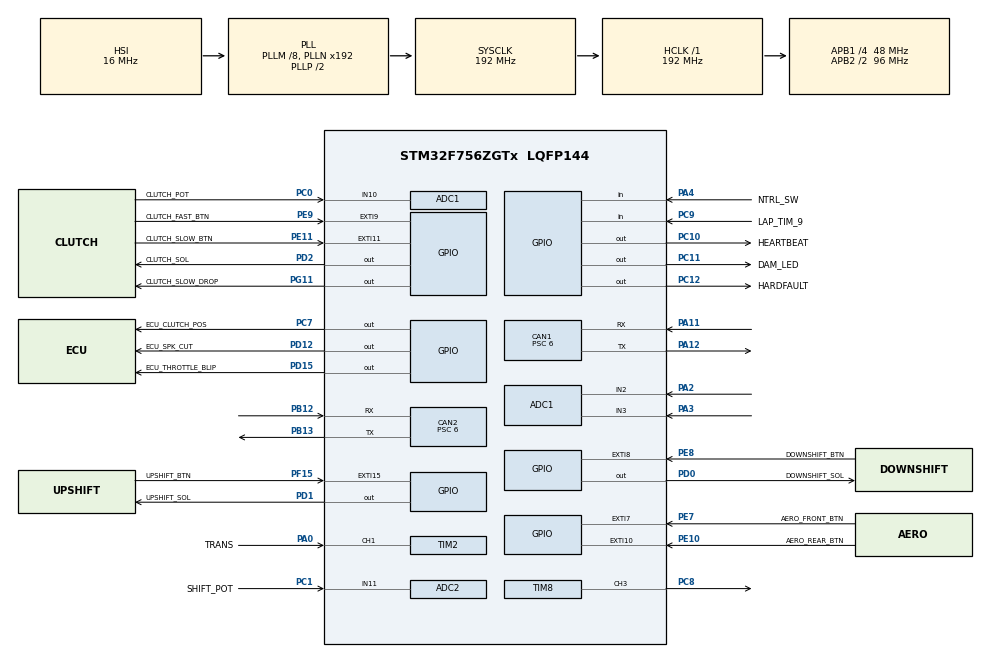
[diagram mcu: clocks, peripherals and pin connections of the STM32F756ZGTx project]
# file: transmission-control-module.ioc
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ADC1.Channel-1\#ChannelRegularConversion=ADC_CHANNEL_2
ADC1.Channel-2\#ChannelRegularConversion=ADC_CHANNEL_3
ADC1.Channel-3\#ChannelRegularConversion=ADC_CHANNEL_10
ADC1.ContinuousConvMode=ENABLE
ADC1.DMAContinuousRequests=ENABLE
ADC1.NbrOfConversion=3
ADC1.NbrOfConversionFlag=1
ADC1.Rank-1\#ChannelRegularConversion=1
ADC1.Rank-2\#ChannelRegularConversion=2
ADC1.Rank-3\#ChannelRegularConversion=3
ADC1.SamplingTime-1\#ChannelRegularConversion=ADC_SAMPLETIME_15CYCLES
ADC1.SamplingTime-2\#ChannelRegularConversion=ADC_SAMPLETIME_15CYCLES
ADC1.SamplingTime-3\#ChannelRegularConversion=ADC_SAMPLETIME_15CYCLES
ADC1.ScanConvMode=ADC_SCAN_ENABLE
ADC1.master=1
ADC2.Channel-0\#ChannelRegularConversion=ADC_CHANNEL_11
ADC2.ContinuousConvMode=ENABLE
ADC2.DMAContinuousRequests=ENABLE
ADC2.NbrOfConversionFlag=1
ADC2.Rank-0\#ChannelRegularConversion=1
ADC2.SamplingTime-0\#ChannelRegularConversion=ADC_SAMPLETIME_15CYCLES
CAN1.ABOM=ENABLE
CAN1.AWUM=ENABLE
CAN1.BS1=CAN_BS1_6TQ
CAN1.BS2=CAN_BS2_1TQ
CAN1.CalculateBaudRate=1000000
CAN1.CalculateTimeBit=1000
CAN1.CalculateTimeQuantum=125.0
CAN1.Mode=CAN_MODE_NORMAL
CAN1.Prescaler=6
CAN2.BS1=CAN_BS1_6TQ
CAN2.CalculateBaudRate=1000000
CAN2.CalculateTimeBit=1000
CAN2.CalculateTimeQuantum=125.0
CAN2.Prescaler=6
Dma.ADC1.1.Direction=DMA_PERIPH_TO_MEMORY
Dma.ADC1.1.FIFOMode=DMA_FIFOMODE_DISABLE
Dma.ADC1.1.Instance=DMA2_Stream0
Dma.ADC1.1.MemDataAlignment=DMA_MDATAALIGN_HALFWORD
Dma.ADC1.1.MemInc=DMA_MINC_ENABLE
Dma.ADC1.1.Mode=DMA_CIRCULAR
Dma.ADC1.1.PeriphDataAlignment=DMA_PDATAALIGN_HALFWORD
Dma.ADC1.1.PeriphInc=DMA_PINC_DISABLE
Dma.ADC1.1.Priority=DMA_PRIORITY_LOW
Dma.ADC2.0.Direction=DMA_PERIPH_TO_MEMORY
Dma.ADC2.0.FIFOMode=DMA_FIFOMODE_DISABLE
Dma.ADC2.0.Instance=DMA2_Stream2
Dma.ADC2.0.MemDataAlignment=DMA_MDATAALIGN_HALFWORD
Dma.ADC2.0.MemInc=DMA_MINC_ENABLE
Dma.ADC2.0.Mode=DMA_CIRCULAR
Dma.ADC2.0.PeriphDataAlignment=DMA_PDATAALIGN_HALFWORD
Dma.ADC2.0.PeriphInc=DMA_PINC_DISABLE
Dma.ADC2.0.Priority=DMA_PRIORITY_LOW
Dma.Request0=ADC2
Dma.Request1=ADC1
FREERTOS.Tasks01=taskMain_Loop,1,256,task_main_loop,Default,NULL,Dynamic,NULL,NULL;taskGCAN_TX,0,256,task_gcan_tx,Default,NULL,Dynamic,NULL,NULL;taskGCAN_RX,0,256,task_gcan_rx,Default,NULL,Dynamic,NULL,NULL
FREERTOS.configENABLE_FPU=1
FREERTOS.configMINIMAL_STACK_SIZE=256
FREERTOS.configUSE_NEWLIB_REENTRANT=1
Mcu.Family=STM32F7
Mcu.Name=STM32F756ZGTx
Mcu.Package=LQFP144
NVIC.CAN1_RX0_IRQn=true\:5\:0\:false\:false\:true\:true\:true\:true\:true
NVIC.CAN1_RX1_IRQn=true\:5\:0\:false\:false\:true\:true\:true\:true\:true
NVIC.CAN1_TX_IRQn=true\:5\:0\:false\:false\:true\:true\:true\:true\:true
NVIC.CAN2_RX0_IRQn=true\:5\:0\:false\:false\:true\:true\:true\:true\:true
NVIC.CAN2_RX1_IRQn=true\:5\:0\:false\:false\:true\:true\:true\:true\:true
NVIC.CAN2_TX_IRQn=true\:5\:0\:false\:false\:true\:true\:true\:true\:true
NVIC.DMA2_Stream0_IRQn=true\:5\:0\:false\:false\:true\:true\:false\:true\:true
NVIC.DMA2_Stream2_IRQn=true\:5\:0\:false\:false\:true\:true\:false\:true\:true
NVIC.EXTI15_10_IRQn=true\:5\:0\:false\:false\:true\:true\:true\:true\:true
NVIC.EXTI9_5_IRQn=true\:5\:0\:false\:false\:true\:true\:true\:true\:true
NVIC.PriorityGroup=NVIC_PRIORITYGROUP_4
NVIC.TIM1_UP_TIM10_IRQn=true\:5\:0\:false\:false\:true\:true\:true\:true\:true
NVIC.TIM2_IRQn=true\:5\:0\:false\:false\:true\:true\:true\:true\:true
NVIC.TIM6_DAC_IRQn=true\:0\:0\:false\:false\:true\:false\:false\:true\:true
NVIC.TimeBase=TIM6_DAC_IRQn
NVIC.TimeBaseIP=TIM6
PA0/WKUP.GPIO_Label=TRANS
PA0/WKUP.Signal=S_TIM2_CH1_ETR
PA11.Mode=CAN_Activate
PA11.Signal=CAN1_RX
PA12.Mode=CAN_Activate
PA12.Signal=CAN1_TX
PA2.Signal=ADCx_IN2
PA3.Signal=ADCx_IN3
PA4.GPIO_Label=NTRL_SW
PA4.Signal=GPIO_Input
PB12.Mode=CAN_Activate
PB12.Signal=CAN2_RX
PB13.Mode=CAN_Activate
PB13.Signal=CAN2_TX
PC0.GPIO_Label=CLUTCH_POT
PC0.Signal=ADCx_IN10
PC1.GPIO_Label=SHIFT_POT
PC1.Signal=ADCx_IN11
PC10.GPIO_Label=HEARTBEAT
PC10.Signal=GPIO_Output
PC11.GPIO_Label=DAM_LED
PC11.Signal=GPIO_Output
PC12.GPIO_Label=HARDFAULT
PC12.Signal=GPIO_Output
PC7.GPIO_Label=ECU_CLUTCH_POS
PC7.Signal=GPIO_Output
PC8.Signal=S_TIM8_CH3
PC9.GPIO_Label=LAP_TIM_9
PC9.GPIO_PuPd=GPIO_PULLDOWN
PC9.Signal=GPIO_Input
PD0.GPIO_Label=DOWNSHIFT_SOL
PD0.Signal=GPIO_Output
PD1.GPIO_Label=UPSHIFT_SOL
PD1.Signal=GPIO_Output
PD12.GPIO_Label=ECU_SPK_CUT
PD12.Signal=GPIO_Output
PD15.GPIO_Label=ECU_THROTTLE_BLIP
PD15.Signal=GPIO_Output
PD2.GPIO_Label=CLUTCH_SOL
PD2.Signal=GPIO_Output
PE10.GPIO_Label=AERO_REAR_BTN
PE10.GPIO_ModeDefaultEXTI=GPIO_MODE_IT_RISING_FALLING
PE10.Signal=GPXTI10
PE11.GPIO_Label=CLUTCH_SLOW_BTN
PE11.GPIO_ModeDefaultEXTI=GPIO_MODE_IT_RISING_FALLING
PE11.Signal=GPXTI11
PE7.GPIO_Label=AERO_FRONT_BTN
PE7.GPIO_ModeDefaultEXTI=GPIO_MODE_IT_RISING_FALLING
PE7.Signal=GPXTI7
PE8.GPIO_Label=DOWNSHIFT_BTN
PE8.GPIO_ModeDefaultEXTI=GPIO_MODE_IT_RISING_FALLING
PE8.Signal=GPXTI8
PE9.GPIO_Label=CLUTCH_FAST_BTN
PE9.GPIO_ModeDefaultEXTI=GPIO_MODE_IT_RISING_FALLING
PE9.Signal=GPXTI9
PF15.GPIO_Label=UPSHIFT_BTN
PF15.GPIO_ModeDefaultEXTI=GPIO_MODE_IT_RISING_FALLING
PF15.Signal=GPXTI15
PG11.GPIO_Label=CLUTCH_SLOW_DROP
PG11.Signal=GPIO_Output
ProjectManager.HeapSize=0x200
ProjectManager.StackSize=0x400
ProjectManager.TargetToolchain=STM32CubeIDE
RCC.AHBFreq_Value=192000000
RCC.APB1CLKDivider=RCC_HCLK_DIV4
RCC.APB1Freq_Value=48000000
RCC.APB1TimFreq_Value=96000000
RCC.APB2CLKDivider=RCC_HCLK_DIV2
RCC.APB2Freq_Value=96000000
RCC.APB2TimFreq_Value=192000000
RCC.CortexFreq_Value=192000000
RCC.HCLKFreq_Value=192000000
RCC.HSE_VALUE=25000000
RCC.HSI_VALUE=16000000
RCC.LSE_VALUE=32768
RCC.PLLM=8
RCC.PLLSAIN=50
RCC.SYSCLKFreq_VALUE=192000000
RCC.SYSCLKSource=RCC_SYSCLKSOURCE_PLLCLK
RCC.USBFreq_Value=192000000
RCC.VCOOutputFreq_Value=384000000
SH.ADCx_IN10.0=ADC1_IN10,IN10
SH.ADCx_IN11.0=ADC2_IN11,IN11
SH.ADCx_IN2.0=ADC1_IN2,IN2
SH.ADCx_IN3.0=ADC1_IN3,IN3
SH.S_TIM2_CH1_ETR.0=TIM2_CH1,Input_Capture1_from_TI1
SH.S_TIM8_CH3.0=TIM8_CH3,PWM Generation3 CH3
TIM2.Channel-Input_Capture1_from_TI1=TIM_CHANNEL_1
TIM2.Prescaler=6-1
TIM8.Channel-PWM\ Generation3\ CH3=TIM_CHANNEL_3
TIM8.Period=20000
TIM8.Prescaler=96
VP_FREERTOS_VS_CMSIS_V1.Mode=CMSIS_V1
VP_SYS_VS_tim6.Mode=TIM6
VP_TIM10_VS_ClockSourceINT.Mode=Enable_Timer
VP_TIM2_VS_ClockSourceINT.Mode=Internal
VP_TIM8_VS_ClockSourceINT.Mode=Internal
board=custom

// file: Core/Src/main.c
/* USER CODE BEGIN Header */
/**
  ******************************************************************************
  * @file           : main.c
  * @brief          : Main program body
  ******************************************************************************
  * @attention
  *
  * <h2><center>&copy; Copyright (c) 2021 STMicroelectronics.
  * All rights reserved.</center></h2>
  *
  * This software component is licensed by ST under BSD 3-Clause license,
  * the "License"; You may not use this file except in compliance with the
  * License. You may obtain a copy of the License at:
  *                        opensource.org/licenses/BSD-3-Clause
  *
  ******************************************************************************
  */
/* USER CODE END Header */
#include "main.h"
#include "cmsis_os.h"

/* USER CODE BEGIN Includes */
#include "DAM.h"
#include "main_task.h"

/* USER CODE END Includes */

 ADC_HandleTypeDef hadc1;
ADC_HandleTypeDef hadc2;
DMA_HandleTypeDef hdma_adc1;
DMA_HandleTypeDef hdma_adc2;

CAN_HandleTypeDef hcan1;
CAN_HandleTypeDef hcan2;

TIM_HandleTypeDef htim2;
TIM_HandleTypeDef htim8;
TIM_HandleTypeDef htim10;

osThreadId taskMain_LoopHandle;
osThreadId taskGCAN_TXHandle;
osThreadId taskGCAN_RXHandle;

void SystemClock_Config(void);
static void MX_GPIO_Init(void);
static void MX_DMA_Init(void);
static void MX_CAN1_Init(void);
static void MX_ADC1_Init(void);
static void MX_ADC2_Init(void);
static void MX_TIM10_Init(void);
static void MX_TIM2_Init(void);
static void MX_CAN2_Init(void);
static void MX_TIM8_Init(void);
void task_main_loop(void const * argument);
void task_gcan_tx(void const * argument);
void task_gcan_rx(void const * argument);

int main(void)
{

  /* MCU Configuration--------------------------------------------------------*/

  /* Reset of all peripherals, Initializes the Flash interface and the Systick. */
  HAL_Init();

  /* Configure the system clock */
  SystemClock_Config();

  /* USER CODE BEGIN SysInit */
  MX_DMA_Init();
  /* USER CODE END SysInit */

  /* Initialize all configured peripherals */
  MX_GPIO_Init();
  MX_DMA_Init();
  MX_CAN1_Init();
  MX_ADC1_Init();
  MX_ADC2_Init();
  MX_TIM10_Init();
  MX_TIM2_Init();
  MX_CAN2_Init();
  MX_TIM8_Init();
  /* USER CODE BEGIN 2 */
  HAL_TIM_IC_Start_IT(&htim2, TIM_CHANNEL_1);
  init_main_task();
  DAM_init(&hcan1, &hcan2, &hadc1, &hadc2, NULL, &htim10, DAM_LED_GPIO_Port, DAM_LED_Pin);

  /* USER CODE END 2 */

  /* Create the thread(s) */
  /* definition and creation of taskMain_Loop */
  osThreadDef(taskMain_Loop, task_main_loop, osPriorityAboveNormal, 0, 256);
  taskMain_LoopHandle = osThreadCreate(osThread(taskMain_Loop), NULL);

  /* definition and creation of taskGCAN_TX */
  osThreadDef(taskGCAN_TX, task_gcan_tx, osPriorityNormal, 0, 256);
  taskGCAN_TXHandle = osThreadCreate(osThread(taskGCAN_TX), NULL);

  /* definition and creation of taskGCAN_RX */
  osThreadDef(taskGCAN_RX, task_gcan_rx, osPriorityNormal, 0, 256);
  taskGCAN_RXHandle = osThreadCreate(osThread(taskGCAN_RX), NULL);

  /* Start scheduler */
  osKernelStart();

  /* We should never get here as control is now taken by the scheduler */
  /* Infinite loop */
  while (1)
  {

  }
}

void SystemClock_Config(void)
{
  RCC_OscInitTypeDef RCC_OscInitStruct = {0};
  RCC_ClkInitTypeDef RCC_ClkInitStruct = {0};

  /** Configure the main internal regulator output voltage
  */
  __HAL_RCC_PWR_CLK_ENABLE();
  __HAL_PWR_VOLTAGESCALING_CONFIG(PWR_REGULATOR_VOLTAGE_SCALE1);

  /** Initializes the RCC Oscillators according to the specified parameters
  * in the RCC_OscInitTypeDef structure.
  */
  RCC_OscInitStruct.OscillatorType = RCC_OSCILLATORTYPE_HSI;
  RCC_OscInitStruct.HSIState = RCC_HSI_ON;
  RCC_OscInitStruct.HSICalibrationValue = RCC_HSICALIBRATION_DEFAULT;
  RCC_OscInitStruct.PLL.PLLState = RCC_PLL_ON;
  RCC_OscInitStruct.PLL.PLLSource = RCC_PLLSOURCE_HSI;
  RCC_OscInitStruct.PLL.PLLM = 8;
  RCC_OscInitStruct.PLL.PLLN = 192;
  RCC_OscInitStruct.PLL.PLLP = RCC_PLLP_DIV2;
  RCC_OscInitStruct.PLL.PLLQ = 2;
  if (HAL_RCC_OscConfig(&RCC_OscInitStruct) != HAL_OK)
  {
    Error_Handler();
  }

  /** Activate the Over-Drive mode
  */
  if (HAL_PWREx_EnableOverDrive() != HAL_OK)
  {
    Error_Handler();
  }

  /** Initializes the CPU, AHB and APB buses clocks
  */
  RCC_ClkInitStruct.ClockType = RCC_CLOCKTYPE_HCLK|RCC_CLOCKTYPE_SYSCLK
                              |RCC_CLOCKTYPE_PCLK1|RCC_CLOCKTYPE_PCLK2;
  RCC_ClkInitStruct.SYSCLKSource = RCC_SYSCLKSOURCE_PLLCLK;
  RCC_ClkInitStruct.AHBCLKDivider = RCC_SYSCLK_DIV1;
  RCC_ClkInitStruct.APB1CLKDivider = RCC_HCLK_DIV4;
  RCC_ClkInitStruct.APB2CLKDivider = RCC_HCLK_DIV2;

  if (HAL_RCC_ClockConfig(&RCC_ClkInitStruct, FLASH_LATENCY_6) != HAL_OK)
  {
    Error_Handler();
  }
}

static void MX_ADC1_Init(void)
{

  ADC_ChannelConfTypeDef sConfig = {0};

  /** Configure the global features of the ADC (Clock, Resolution, Data Alignment and number of conversion)
  */
  hadc1.Instance = ADC1;
  hadc1.Init.ClockPrescaler = ADC_CLOCK_SYNC_PCLK_DIV4;
  hadc1.Init.Resolution = ADC_RESOLUTION_12B;
  hadc1.Init.ScanConvMode = ADC_SCAN_ENABLE;
  hadc1.Init.ContinuousConvMode = ENABLE;
  hadc1.Init.DiscontinuousConvMode = DISABLE;
  hadc1.Init.ExternalTrigConvEdge = ADC_EXTERNALTRIGCONVEDGE_NONE;
  hadc1.Init.ExternalTrigConv = ADC_SOFTWARE_START;
  hadc1.Init.DataAlign = ADC_DATAALIGN_RIGHT;
  hadc1.Init.NbrOfConversion = 3;
  hadc1.Init.DMAContinuousRequests = ENABLE;
  hadc1.Init.EOCSelection = ADC_EOC_SINGLE_CONV;
  if (HAL_ADC_Init(&hadc1) != HAL_OK)
  {
    Error_Handler();
  }

  /** Configure for the selected ADC regular channel its corresponding rank in the sequencer and its sample time.
  */
  sConfig.Channel = ADC_CHANNEL_2;
  sConfig.Rank = ADC_REGULAR_RANK_1;
  sConfig.SamplingTime = ADC_SAMPLETIME_15CYCLES;
  if (HAL_ADC_ConfigChannel(&hadc1, &sConfig) != HAL_OK)
  {
    Error_Handler();
  }

  /** Configure for the selected ADC regular channel its corresponding rank in the sequencer and its sample time.
  */
  sConfig.Channel = ADC_CHANNEL_3;
  sConfig.Rank = ADC_REGULAR_RANK_2;
  if (HAL_ADC_ConfigChannel(&hadc1, &sConfig) != HAL_OK)
  {
    Error_Handler();
  }

  /** Configure for the selected ADC regular channel its corresponding rank in the sequencer and its sample time.
  */
  sConfig.Channel = ADC_CHANNEL_10;
  sConfig.Rank = ADC_REGULAR_RANK_3;
  if (HAL_ADC_ConfigChannel(&hadc1, &sConfig) != HAL_OK)
  {
    Error_Handler();
  }

}

static void MX_ADC2_Init(void)
{

  ADC_ChannelConfTypeDef sConfig = {0};

  /** Configure the global features of the ADC (Clock, Resolution, Data Alignment and number of conversion)
  */
  hadc2.Instance = ADC2;
  hadc2.Init.ClockPrescaler = ADC_CLOCK_SYNC_PCLK_DIV4;
  hadc2.Init.Resolution = ADC_RESOLUTION_12B;
  hadc2.Init.ScanConvMode = ADC_SCAN_DISABLE;
  hadc2.Init.ContinuousConvMode = ENABLE;
  hadc2.Init.DiscontinuousConvMode = DISABLE;
  hadc2.Init.ExternalTrigConvEdge = ADC_EXTERNALTRIGCONVEDGE_NONE;
  hadc2.Init.ExternalTrigConv = ADC_SOFTWARE_START;
  hadc2.Init.DataAlign = ADC_DATAALIGN_RIGHT;
  hadc2.Init.NbrOfConversion = 1;
  hadc2.Init.DMAContinuousRequests = ENABLE;
  hadc2.Init.EOCSelection = ADC_EOC_SINGLE_CONV;
  if (HAL_ADC_Init(&hadc2) != HAL_OK)
  {
    Error_Handler();
  }

  /** Configure for the selected ADC regular channel its corresponding rank in the sequencer and its sample time.
  */
  sConfig.Channel = ADC_CHANNEL_11;
  sConfig.Rank = ADC_REGULAR_RANK_1;
  sConfig.SamplingTime = ADC_SAMPLETIME_15CYCLES;
  if (HAL_ADC_ConfigChannel(&hadc2, &sConfig) != HAL_OK)
  {
    Error_Handler();
  }

}

static void MX_CAN1_Init(void)
{

  hcan1.Instance = CAN1;
  hcan1.Init.Prescaler = 6;
  hcan1.Init.Mode = CAN_MODE_NORMAL;
  hcan1.Init.SyncJumpWidth = CAN_SJW_1TQ;
  hcan1.Init.TimeSeg1 = CAN_BS1_6TQ;
  hcan1.Init.TimeSeg2 = CAN_BS2_1TQ;
  hcan1.Init.TimeTriggeredMode = DISABLE;
  hcan1.Init.AutoBusOff = ENABLE;
  hcan1.Init.AutoWakeUp = ENABLE;
  hcan1.Init.AutoRetransmission = DISABLE;
  hcan1.Init.ReceiveFifoLocked = DISABLE;
  hcan1.Init.TransmitFifoPriority = DISABLE;
  if (HAL_CAN_Init(&hcan1) != HAL_OK)
  {
    Error_Handler();
  }

}

static void MX_CAN2_Init(void)
{

  hcan2.Instance = CAN2;
  hcan2.Init.Prescaler = 6;
  hcan2.Init.Mode = CAN_MODE_NORMAL;
  hcan2.Init.SyncJumpWidth = CAN_SJW_1TQ;
  hcan2.Init.TimeSeg1 = CAN_BS1_6TQ;
  hcan2.Init.TimeSeg2 = CAN_BS2_1TQ;
  hcan2.Init.TimeTriggeredMode = DISABLE;
  hcan2.Init.AutoBusOff = DISABLE;
  hcan2.Init.AutoWakeUp = DISABLE;
  hcan2.Init.AutoRetransmission = DISABLE;
  hcan2.Init.ReceiveFifoLocked = DISABLE;
  hcan2.Init.TransmitFifoPriority = DISABLE;
  if (HAL_CAN_Init(&hcan2) != HAL_OK)
  {
    Error_Handler();
  }

}

static void MX_TIM2_Init(void)
{

  TIM_ClockConfigTypeDef sClockSourceConfig = {0};
  TIM_MasterConfigTypeDef sMasterConfig = {0};
  TIM_IC_InitTypeDef sConfigIC = {0};

  htim2.Instance = TIM2;
  htim2.Init.Prescaler = 6-1;
  htim2.Init.CounterMode = TIM_COUNTERMODE_UP;
  htim2.Init.Period = 4294967295;
  htim2.Init.ClockDivision = TIM_CLOCKDIVISION_DIV1;
  htim2.Init.AutoReloadPreload = TIM_AUTORELOAD_PRELOAD_DISABLE;
  if (HAL_TIM_Base_Init(&htim2) != HAL_OK)
  {
    Error_Handler();
  }
  sClockSourceConfig.ClockSource = TIM_CLOCKSOURCE_INTERNAL;
  if (HAL_TIM_ConfigClockSource(&htim2, &sClockSourceConfig) != HAL_OK)
  {
    Error_Handler();
  }
  if (HAL_TIM_IC_Init(&htim2) != HAL_OK)
  {
    Error_Handler();
  }
  sMasterConfig.MasterOutputTrigger = TIM_TRGO_RESET;
  sMasterConfig.MasterSlaveMode = TIM_MASTERSLAVEMODE_DISABLE;
  if (HAL_TIMEx_MasterConfigSynchronization(&htim2, &sMasterConfig) != HAL_OK)
  {
    Error_Handler();
  }
  sConfigIC.ICPolarity = TIM_INPUTCHANNELPOLARITY_RISING;
  sConfigIC.ICSelection = TIM_ICSELECTION_DIRECTTI;
  sConfigIC.ICPrescaler = TIM_ICPSC_DIV1;
  sConfigIC.ICFilter = 0;
  if (HAL_TIM_IC_ConfigChannel(&htim2, &sConfigIC, TIM_CHANNEL_1) != HAL_OK)
  {
    Error_Handler();
  }

}

static void MX_TIM8_Init(void)
{

  TIM_ClockConfigTypeDef sClockSourceConfig = {0};
  TIM_MasterConfigTypeDef sMasterConfig = {0};
  TIM_OC_InitTypeDef sConfigOC = {0};
  TIM_BreakDeadTimeConfigTypeDef sBreakDeadTimeConfig = {0};

  htim8.Instance = TIM8;
  htim8.Init.Prescaler = 96;
  htim8.Init.CounterMode = TIM_COUNTERMODE_UP;
  htim8.Init.Period = 20000;
  htim8.Init.ClockDivision = TIM_CLOCKDIVISION_DIV1;
  htim8.Init.RepetitionCounter = 0;
  htim8.Init.AutoReloadPreload = TIM_AUTORELOAD_PRELOAD_DISABLE;
  if (HAL_TIM_Base_Init(&htim8) != HAL_OK)
  {
    Error_Handler();
  }
  sClockSourceConfig.ClockSource = TIM_CLOCKSOURCE_INTERNAL;
  if (HAL_TIM_ConfigClockSource(&htim8, &sClockSourceConfig) != HAL_OK)
  {
    Error_Handler();
  }
  if (HAL_TIM_PWM_Init(&htim8) != HAL_OK)
  {
    Error_Handler();
  }
  sMasterConfig.MasterOutputTrigger = TIM_TRGO_RESET;
  sMasterConfig.MasterOutputTrigger2 = TIM_TRGO2_RESET;
  sMasterConfig.MasterSlaveMode = TIM_MASTERSLAVEMODE_DISABLE;
  if (HAL_TIMEx_MasterConfigSynchronization(&htim8, &sMasterConfig) != HAL_OK)
  {
    Error_Handler();
  }
  sConfigOC.OCMode = TIM_OCMODE_PWM1;
  sConfigOC.Pulse = 0;
  sConfigOC.OCPolarity = TIM_OCPOLARITY_HIGH;
  sConfigOC.OCNPolarity = TIM_OCNPOLARITY_HIGH;
  sConfigOC.OCFastMode = TIM_OCFAST_DISABLE;
  sConfigOC.OCIdleState = TIM_OCIDLESTATE_RESET;
  sConfigOC.OCNIdleState = TIM_OCNIDLESTATE_RESET;
  if (HAL_TIM_PWM_ConfigChannel(&htim8, &sConfigOC, TIM_CHANNEL_3) != HAL_OK)
  {
    Error_Handler();
  }
  sBreakDeadTimeConfig.OffStateRunMode = TIM_OSSR_DISABLE;
  sBreakDeadTimeConfig.OffStateIDLEMode = TIM_OSSI_DISABLE;
  sBreakDeadTimeConfig.LockLevel = TIM_LOCKLEVEL_OFF;
  sBreakDeadTimeConfig.DeadTime = 0;
  sBreakDeadTimeConfig.BreakState = TIM_BREAK_DISABLE;
  sBreakDeadTimeConfig.BreakPolarity = TIM_BREAKPOLARITY_HIGH;
  sBreakDeadTimeConfig.BreakFilter = 0;
  sBreakDeadTimeConfig.Break2State = TIM_BREAK2_DISABLE;
  sBreakDeadTimeConfig.Break2Polarity = TIM_BREAK2POLARITY_HIGH;
  sBreakDeadTimeConfig.Break2Filter = 0;
  sBreakDeadTimeConfig.AutomaticOutput = TIM_AUTOMATICOUTPUT_DISABLE;
  if (HAL_TIMEx_ConfigBreakDeadTime(&htim8, &sBreakDeadTimeConfig) != HAL_OK)
  {
    Error_Handler();
  }
  HAL_TIM_MspPostInit(&htim8);

}

static void MX_TIM10_Init(void)
{

  htim10.Instance = TIM10;
  htim10.Init.Prescaler = 0;
  htim10.Init.CounterMode = TIM_COUNTERMODE_UP;
  htim10.Init.Period = 65535;
  htim10.Init.ClockDivision = TIM_CLOCKDIVISION_DIV1;
  htim10.Init.AutoReloadPreload = TIM_AUTORELOAD_PRELOAD_DISABLE;
  if (HAL_TIM_Base_Init(&htim10) != HAL_OK)
  {
    Error_Handler();
  }

}

static void MX_DMA_Init(void)
{

  /* DMA controller clock enable */
  __HAL_RCC_DMA2_CLK_ENABLE();

  /* DMA interrupt init */
  /* DMA2_Stream0_IRQn interrupt configuration */
  HAL_NVIC_SetPriority(DMA2_Stream0_IRQn, 5, 0);
  HAL_NVIC_EnableIRQ(DMA2_Stream0_IRQn);
  /* DMA2_Stream2_IRQn interrupt configuration */
  HAL_NVIC_SetPriority(DMA2_Stream2_IRQn, 5, 0);
  HAL_NVIC_EnableIRQ(DMA2_Stream2_IRQn);

}

static void MX_GPIO_Init(void)
{
  GPIO_InitTypeDef GPIO_InitStruct = {0};

  /* GPIO Ports Clock Enable */
  __HAL_RCC_GPIOC_CLK_ENABLE();
  __HAL_RCC_GPIOA_CLK_ENABLE();
  __HAL_RCC_GPIOF_CLK_ENABLE();
  __HAL_RCC_GPIOE_CLK_ENABLE();
  __HAL_RCC_GPIOB_CLK_ENABLE();
  __HAL_RCC_GPIOD_CLK_ENABLE();
  __HAL_RCC_GPIOG_CLK_ENABLE();

  /*Configure GPIO pin Output Level */
  HAL_GPIO_WritePin(GPIOD, ECU_SPK_CUT_Pin|ECU_THROTTLE_BLIP_Pin|DOWNSHIFT_SOL_Pin|UPSHIFT_SOL_Pin
                          |CLUTCH_SOL_Pin, GPIO_PIN_RESET);

  /*Configure GPIO pin Output Level */
  HAL_GPIO_WritePin(GPIOC, ECU_CLUTCH_POS_Pin|HEARTBEAT_Pin|DAM_LED_Pin|HARDFAULT_Pin, GPIO_PIN_RESET);

  /*Configure GPIO pin Output Level */
  HAL_GPIO_WritePin(CLUTCH_SLOW_DROP_GPIO_Port, CLUTCH_SLOW_DROP_Pin, GPIO_PIN_RESET);

  /*Configure GPIO pin : NTRL_SW_Pin */
  GPIO_InitStruct.Pin = NTRL_SW_Pin;
  GPIO_InitStruct.Mode = GPIO_MODE_INPUT;
  GPIO_InitStruct.Pull = GPIO_NOPULL;
  HAL_GPIO_Init(NTRL_SW_GPIO_Port, &GPIO_InitStruct);

  /*Configure GPIO pin : UPSHIFT_BTN_Pin */
  GPIO_InitStruct.Pin = UPSHIFT_BTN_Pin;
  GPIO_InitStruct.Mode = GPIO_MODE_IT_RISING_FALLING;
  GPIO_InitStruct.Pull = GPIO_NOPULL;
  HAL_GPIO_Init(UPSHIFT_BTN_GPIO_Port, &GPIO_InitStruct);

  /*Configure GPIO pins : AERO_FRONT_BTN_Pin DOWNSHIFT_BTN_Pin CLUTCH_FAST_BTN_Pin AERO_REAR_BTN_Pin
                           CLUTCH_SLOW_BTN_Pin */
  GPIO_InitStruct.Pin = AERO_FRONT_BTN_Pin|DOWNSHIFT_BTN_Pin|CLUTCH_FAST_BTN_Pin|AERO_REAR_BTN_Pin
                          |CLUTCH_SLOW_BTN_Pin;
  GPIO_InitStruct.Mode = GPIO_MODE_IT_RISING_FALLING;
  GPIO_InitStruct.Pull = GPIO_NOPULL;
  HAL_GPIO_Init(GPIOE, &GPIO_InitStruct);

  /*Configure GPIO pins : ECU_SPK_CUT_Pin ECU_THROTTLE_BLIP_Pin DOWNSHIFT_SOL_Pin UPSHIFT_SOL_Pin
                           CLUTCH_SOL_Pin */
  GPIO_InitStruct.Pin = ECU_SPK_CUT_Pin|ECU_THROTTLE_BLIP_Pin|DOWNSHIFT_SOL_Pin|UPSHIFT_SOL_Pin
                          |CLUTCH_SOL_Pin;
  GPIO_InitStruct.Mode = GPIO_MODE_OUTPUT_PP;
  GPIO_InitStruct.Pull = GPIO_NOPULL;
  GPIO_InitStruct.Speed = GPIO_SPEED_FREQ_LOW;
  HAL_GPIO_Init(GPIOD, &GPIO_InitStruct);

  /*Configure GPIO pins : ECU_CLUTCH_POS_Pin HEARTBEAT_Pin DAM_LED_Pin HARDFAULT_Pin */
  GPIO_InitStruct.Pin = ECU_CLUTCH_POS_Pin|HEARTBEAT_Pin|DAM_LED_Pin|HARDFAULT_Pin;
  GPIO_InitStruct.Mode = GPIO_MODE_OUTPUT_PP;
  GPIO_InitStruct.Pull = GPIO_NOPULL;
  GPIO_InitStruct.Speed = GPIO_SPEED_FREQ_LOW;
  HAL_GPIO_Init(GPIOC, &GPIO_InitStruct);

  /*Configure GPIO pin : LAP_TIM_9_Pin */
  GPIO_InitStruct.Pin = LAP_TIM_9_Pin;
  GPIO_InitStruct.Mode = GPIO_MODE_INPUT;
  GPIO_InitStruct.Pull = GPIO_PULLDOWN;
  HAL_GPIO_Init(LAP_TIM_9_GPIO_Port, &GPIO_InitStruct);

  /*Configure GPIO pin : CLUTCH_SLOW_DROP_Pin */
  GPIO_InitStruct.Pin = CLUTCH_SLOW_DROP_Pin;
  GPIO_InitStruct.Mode = GPIO_MODE_OUTPUT_PP;
  GPIO_InitStruct.Pull = GPIO_NOPULL;
  GPIO_InitStruct.Speed = GPIO_SPEED_FREQ_LOW;
  HAL_GPIO_Init(CLUTCH_SLOW_DROP_GPIO_Port, &GPIO_InitStruct);

  /* EXTI interrupt init*/
  HAL_NVIC_SetPriority(EXTI9_5_IRQn, 5, 0);
  HAL_NVIC_EnableIRQ(EXTI9_5_IRQn);

  HAL_NVIC_SetPriority(EXTI15_10_IRQn, 5, 0);
  HAL_NVIC_EnableIRQ(EXTI15_10_IRQn);

}

void task_main_loop(void const * argument)
{
  /* USER CODE BEGIN 5 */
  /* Infinite loop */
  for(;;)
  {
	  main_task();
	  osDelay(1);
  }
  /* USER CODE END 5 */
}

void task_gcan_tx(void const * argument)
{
  /* USER CODE BEGIN task_gcan_tx */
  /* Infinite loop */
  for(;;)
  {
	gopherCAN_tx_service_task();
    osDelay(1);
  }
  /* USER CODE END task_gcan_tx */
}

void task_gcan_rx(void const * argument)
{
  /* USER CODE BEGIN task_gcan_rx */
  /* Infinite loop */
  for(;;)
  {
	gopherCAN_rx_buffer_service_task();
    osDelay(1);
  }
  /* USER CODE END task_gcan_rx */
}

void HAL_TIM_PeriodElapsedCallback(TIM_HandleTypeDef *htim)
{
  if (htim->Instance == TIM6) {
    HAL_IncTick();
  }
  /* USER CODE BEGIN Callback 1 */
  else
  {
	  DAQ_TimerCallback(htim);
  }
  /* USER CODE END Callback 1 */
}

void Error_Handler(void)
{
  __disable_irq();
  while (1)
  {
  }
}
